# AC7802x register map
Vendor: AutoChips; Series: AC78; File version: 1.0
CPU: CM0PLUS r0p1, little endian, no MPU, no FPU, VTOR, 2 interrupt priority bits
Registers are 32-bit, read-write, reset 0x0 unless marked. A register's access mark holds for its fields unless they carry their own. Offsets are from the block's base; [hi:lo] are bit positions; {n}, {i} and the like mark numbered series.

## SPI0 — Serial Peripheral Interface
Base 0x4000C000
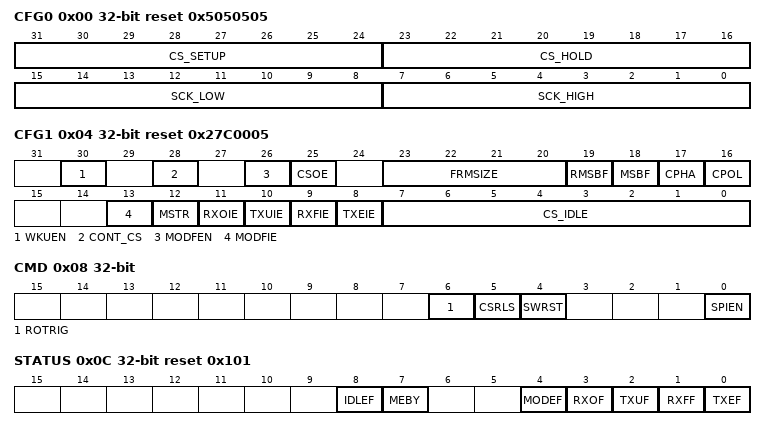
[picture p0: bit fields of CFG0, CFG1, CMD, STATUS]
0x00 CFG0 reset 0x5050505 — SPI Configuration Register 0
  [31:24] CS_SETUP — CS Setup Count
  [23:16] CS_HOLD — CS hold count
  [15:8] SCK_LOW — SCK low count
  [7:0] SCK_HIGH — SCK High Count
0x04 CFG1 reset 0x27C0005 — SPI Configuration Register 1
  [30] WKUEN — wake up function enable(only valid for slave mode)
  [28] CONT_CS — CS continuous output enable
  [26] MODFEN — mode fault detect enable
  [25] CSOE — CS hardware output enable
  [23:20] FRMSIZE — frame size
    {v}=Frame size is 4 bits (v=0..3); {v}=Frame size is {v+1} bits (v=4..15)
  [19] RMSBF — RX MSB first Select
  [18] MSBF — TX MSB first Select
  [17] CPHA — clock phase
    0=the second SCK transition is the first data capture edge; 1=the first SCK transition is the first data capture edge
  [16] CPOL — clock polarity
    0=SCK is 0 when idle; 1=SCK is 1 when idle
  [13] MODFIE — mode fault interrupt enable
  [12] MSTR — master/slave mode selection
    0=SLAVE (SPI slave mode); 1=MASTER (SPI master mode)
  [11] RXOIE — RX buffer overflow interrupt enable
  [10] TXUIE — TX buffer underflow interrupt enable
  [9] RXFIE — RX buffer full interrupt enable
  [8] TXEIE — TX buffer empty interrupt enable
  [7:0] CS_IDLE — CS idle count
0x08 CMD — SPI Command Register
  [6] ROTRIG — Master RX only mode edge
  [5] CSRLS — CS release(only valid for CS continuous output)
  [4] SWRST — software reset
  [0] SPIEN — SPI Enable
0x0C STATUS reset 0x101 — SPI Status Register
  [8] IDLEF ro — SPI IDLE flag
  [7] MEBY ro — SPI master engine busy flag
  [4] MODEF ro — Mode error flag
  [3] RXOF — RX buffer overflow flag
  [2] TXUF — TX buffer underflow flag
  [1] RXFF ro — RX buffer Full flag
  [0] TXEF ro — TX buffer empty flag
0x10 DATA — SPI Data Register
  [15:0] DATA
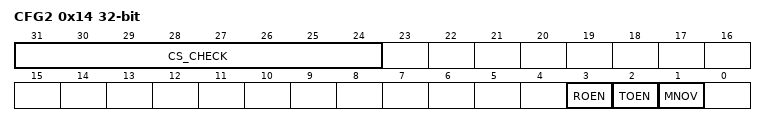
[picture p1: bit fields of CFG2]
0x14 CFG2 reset not defined — SPI configuration register 2
  [31:24] CS_CHECK — CS Check Count
  [3] ROEN — RX only mode enable bit
  [2] TOEN — TX only mode enable bit
  [1] MNOV — Master No Overflow mode enable bit

## ACMP0 — Analog comparator
Base 0x40005000
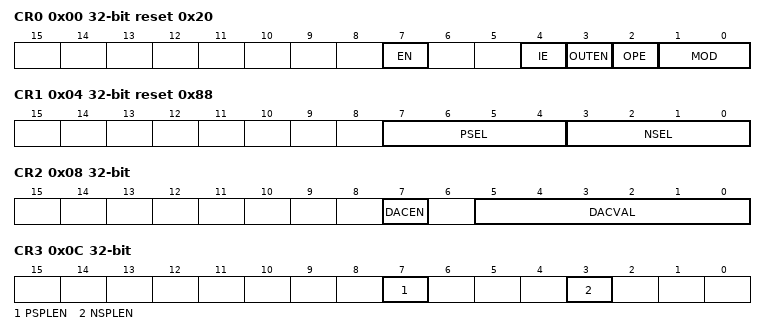
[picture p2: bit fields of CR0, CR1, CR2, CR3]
0x00 CR0 reset 0x20 — ACMP Configuration Register 0
  [7] EN — Analog Comparator Enable
    0=ACMP is disabled; 1=ACMP is enabled
  [4] IE — ACMP Interrupt Enable
    0=Disable the ACMP Interrupt; 1=Enable the ACMP Interrupt
  [3] OUTEN — ACMP Output Enable
    0=Disable ACMP OUTPUT; 1=Enable ACMP OUTPUT
  [2] OPE — ACMP hall output Enable
    0=ACMP hall output Disabled; 1=ACMP hall output enabled
  [1:0] MOD — ACMP sensitivity modes of the interrupt trigger
    0=ACMP interrupt on output falling edge; 1=ACMP interrupt on output rising edge; 2=ACMP interrupt on output falling edge; 3=ACMP interrupt on output falling or rising edge
0x04 CR1 reset 0x88 — ACMP Configuration Register 1
  [7:4] PSEL — ACMP Positive Input Select
    {v}=External input {v} (v=0..7); 8=DAC0 output
  [3:0] NSEL — ACMP Negative Input Select
    {v}=External input {v} (v=0..7); 8=DAC0 output
0x08 CR2 — ACMP configuration register 2
  [7] DACEN — DAC Enable
    0=The DAC is disabled; 1=The DAC is enabled
  [5:0] DACVAL — DAC Output Value
0x0C CR3 — ACMP configuration register 3
  [7] PSPLEN — ACMP positive input polling mode enable
    0=ACMP positive input polling mode disabled; 1=ACMP positive input polling mode enabled
  [3] NSPLEN — ACMP negative input polling mode enable
    0=ACMP negative input polling mode disabled; 1=ACMP negative input polling mode enabled
0x10 CR4 — ACMP configuration register 4
  [8:0] PLSEQ — ACMP polling channel sequence set
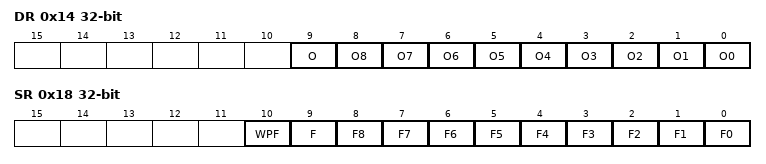
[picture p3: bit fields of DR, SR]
0x14 DR ro — ACMP data output register 0
  [9] O — ACMP normal mode output
  [8] O8 — ACMP polling mode DAC0 output
  [n] O{n} (n=0..7) — ACMP polling mode channel {n} output
0x18 SR — ACMP status register 0
  [10] WPF — ACMP low power mode wakeup interrupt flag
  [9] F — ACMP normal mode interrupt flag
  [8] F8 — ACMP polling mode DAC0 interrupt flag
  [n] F{n} (n=0..7) — ACMP polling mode channel {n} interrupt flag
0x1C FD — ACMP polling frequency divider register
  [1:0] PLFD — ACMP polling mode frequency divider
    0=source_clk/171; 1=source_clk/67; 2=source_clk/47; 3=source_clk/34
0x20 OPA — ACMP hall output A set register
  [3:0] OPASEL — ACMP Hall output A set
    {v}=polling channel {v} (v=0..7); 8=polling DAC0
0x24 OPB — ACMP hall output B set register
  [3:0] OPBSEL — ACMP Hall output B set
    {v}=polling channel {v} (v=0..7); 8=polling DAC0
0x28 OPC — ACMP hall output C set register
  [3:0] OPCSEL — ACMP Hall output C set
    {v}=polling channel {v} (v=0..7); 8=polling DAC0
0x2C DACSR — ACMP DAC reference select register
  [0] DACREF — DAC reference select
    0=The DAC selects bandgap as the reference; 1=The DAC selects Vdd as the reference
